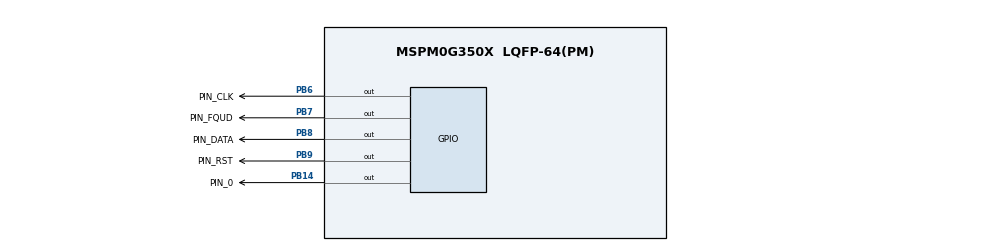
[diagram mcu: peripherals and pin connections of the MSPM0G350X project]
/**
 *
 * @cliArgs --device "MSPM0G350X" --part "Default" --package "LQFP-64(PM)" --product "mspm0_sdk@2.11.00.07"
 * @versions {"tool":"1.28.0+4696"}
 */

/**
 * Import the modules used in this configuration.
 */
const GPIO    = scripting.addModule("/ti/driverlib/GPIO", {}, false);
const GPIO1   = GPIO.addInstance();
const GPIO2   = GPIO.addInstance();
const SYSCTL  = scripting.addModule("/ti/driverlib/SYSCTL");
const SYSTICK = scripting.addModule("/ti/driverlib/SYSTICK");

/**
 * Write custom configuration values to the imported modules.
 */
GPIO1.$name                         = "GPIO_DDS";
GPIO1.associatedPins.create(4);
GPIO1.associatedPins[0].$name       = "PIN_CLK";
GPIO1.associatedPins[0].pin.$assign = "PB6";
GPIO1.associatedPins[1].$name       = "PIN_FQUD";
GPIO1.associatedPins[1].pin.$assign = "PB7";
GPIO1.associatedPins[2].$name       = "PIN_DATA";
GPIO1.associatedPins[2].pin.$assign = "PB8";
GPIO1.associatedPins[3].$name       = "PIN_RST";
GPIO1.associatedPins[3].pin.$assign = "PB9";

const Board = scripting.addModule("/ti/driverlib/Board", {}, false);

GPIO2.$name                         = "GPIO_USRLED";
GPIO2.associatedPins[0].$name       = "PIN_0";
GPIO2.associatedPins[0].pin.$assign = "PB14";

SYSCTL.forceDefaultClkConfig = true;

SYSTICK.periodEnable  = true;
SYSTICK.period        = 32000;
SYSTICK.systickEnable = true;

/**
 * Pinmux solution for unlocked pins/peripherals. This ensures that minor changes to the automatic solver in a future
 * version of the tool will not impact the pinmux you originally saw.  These lines can be completely deleted in order to
 * re-solve from scratch.
 */
Board.peripheral.$suggestSolution          = "DEBUGSS";
Board.peripheral.swclkPin.$suggestSolution = "PA20";
Board.peripheral.swdioPin.$suggestSolution = "PA19";
SYSCTL.peripheral.$suggestSolution         = "SYSCTL";
